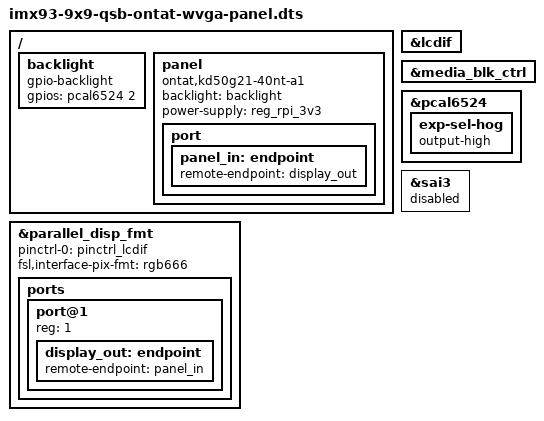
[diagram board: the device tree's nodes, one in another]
// SPDX-License-Identifier: (GPL-2.0+ OR MIT)
/*
 * Copyright 2022 NXP
 */

#include "imx93-9x9-qsb.dts"

/ {
	backlight: backlight {
		compatible = "gpio-backlight";
		gpios = <&pcal6524 2 GPIO_ACTIVE_HIGH>;
	};

	panel: panel {
		compatible = "ontat,kd50g21-40nt-a1";
		backlight = <&backlight>;
		power-supply = <&reg_rpi_3v3>;

		port {
			panel_in: endpoint {
				remote-endpoint = <&display_out>;
			};
		};
	};
};

&lcdif {
	status = "okay";
};

&media_blk_ctrl {
	status = "okay";
};

&parallel_disp_fmt {
	pinctrl-names = "default";
	pinctrl-0 = <&pinctrl_lcdif>;
	fsl,interface-pix-fmt = "rgb666";
	status = "okay";

	ports {
		port@1 {
			reg = <1>;

			display_out: endpoint {
				remote-endpoint = <&panel_in>;
			};
		};
	};
};

&pcal6524 {
	exp-sel-hog {
		/delete-property/ output-low;
		output-high;
	};
};

/* pin conflicts */
&sai3 {
	status = "disabled";
};
